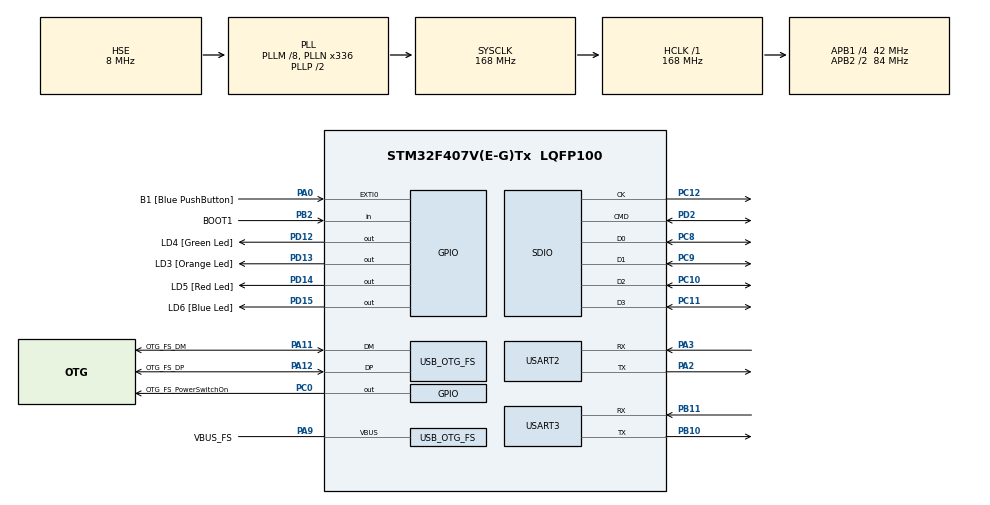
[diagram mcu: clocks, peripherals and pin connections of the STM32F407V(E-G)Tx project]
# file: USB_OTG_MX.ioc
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Mcu.Family=STM32F4
Mcu.Name=STM32F407V(E-G)Tx
Mcu.Package=LQFP100
NVIC.OTG_FS_IRQn=true\:0\:0\:false\:false\:true\:true
NVIC.PriorityGroup=NVIC_PRIORITYGROUP_0
NVIC.USART2_IRQn=true\:0\:0\:false\:false\:true\:true
NVIC.USART3_IRQn=true\:0\:0\:false\:false\:true\:true
PA0-WKUP.GPIO_Label=B1 [Blue PushButton]
PA0-WKUP.GPIO_ModeDefaultEXTI=GPIO_MODE_EVT_RISING
PA0-WKUP.GPIO_PuPd=GPIO_NOPULL
PA0-WKUP.Signal=GPXTI0
PA10.Signal=USB_OTG_FS_ID
PA11.GPIO_Label=OTG_FS_DM
PA11.GPIO_Mode=GPIO_MODE_AF_PP
PA11.GPIO_PuPd=GPIO_NOPULL
PA11.GPIO_Speed=GPIO_SPEED_FREQ_LOW
PA11.Mode=Device_Only
PA11.Signal=USB_OTG_FS_DM
PA12.GPIO_Label=OTG_FS_DP
PA12.GPIO_Mode=GPIO_MODE_AF_PP
PA12.GPIO_PuPd=GPIO_NOPULL
PA12.GPIO_Speed=GPIO_SPEED_FREQ_LOW
PA12.Mode=Device_Only
PA12.Signal=USB_OTG_FS_DP
PA13.GPIO_Label=SWDIO
PA13.Signal=SYS_JTMS-SWDIO
PA14.GPIO_Label=SWCLK
PA14.Signal=SYS_JTCK-SWCLK
PA2.Mode=Asynchronous
PA2.Signal=USART2_TX
PA3.Mode=Asynchronous
PA3.Signal=USART2_RX
PA9.GPIO_Label=VBUS_FS
PA9.GPIO_Mode=GPIO_MODE_INPUT
PA9.GPIO_PuPd=GPIO_NOPULL
PA9.Mode=Activate_VBUS
PA9.Signal=USB_OTG_FS_VBUS
PB10.Mode=Asynchronous
PB10.Signal=USART3_TX
PB11.Mode=Asynchronous
PB11.Signal=USART3_RX
PB2.GPIO_Label=BOOT1
PB2.GPIO_Mode=GPIO_MODE_INPUT
PB2.GPIO_PuPd=GPIO_NOPULL
PB2.Signal=GPIO_Input
PB3.GPIO_Label=SWO
PB3.Signal=SYS_JTDO-SWO
PC0.GPIO_Label=OTG_FS_PowerSwitchOn
PC0.GPIO_PuPd=GPIO_NOPULL
PC0.GPIO_Speed=GPIO_SPEED_FREQ_LOW
PC0.PinState=GPIO_PIN_SET
PC0.Signal=GPIO_Output
PC10.Mode=SD_4_bits_Wide_bus
PC10.Signal=SDIO_D2
PC11.Mode=SD_4_bits_Wide_bus
PC11.Signal=SDIO_D3
PC12.Mode=SD_4_bits_Wide_bus
PC12.Signal=SDIO_CK
PC14-OSC32_IN.GPIO_Label=PC14-OSC32_IN
PC14-OSC32_IN.Signal=RCC_OSC32_IN
PC15-OSC32_OUT.GPIO_Label=PC15-OSC32_OUT
PC15-OSC32_OUT.Signal=RCC_OSC32_OUT
PC8.Mode=SD_4_bits_Wide_bus
PC8.Signal=SDIO_D0
PC9.Mode=SD_4_bits_Wide_bus
PC9.Signal=SDIO_D1
PD12.GPIO_Label=LD4 [Green Led]
PD12.GPIO_PuPd=GPIO_NOPULL
PD12.GPIO_Speed=GPIO_SPEED_FREQ_LOW
PD12.Signal=GPIO_Output
PD13.GPIO_Label=LD3 [Orange Led]
PD13.GPIO_PuPd=GPIO_NOPULL
PD13.GPIO_Speed=GPIO_SPEED_FREQ_LOW
PD13.Signal=GPIO_Output
PD14.GPIO_Label=LD5 [Red Led]
PD14.GPIO_PuPd=GPIO_NOPULL
PD14.GPIO_Speed=GPIO_SPEED_FREQ_LOW
PD14.Signal=GPIO_Output
PD15.GPIO_Label=LD6 [Blue Led]
PD15.GPIO_PuPd=GPIO_NOPULL
PD15.GPIO_Speed=GPIO_SPEED_FREQ_LOW
PD15.Signal=GPIO_Output
PD2.Mode=SD_4_bits_Wide_bus
PD2.Signal=SDIO_CMD
PH0-OSC_IN.GPIO_Label=PH0-OSC_IN
PH0-OSC_IN.Mode=HSE-External-Oscillator
PH0-OSC_IN.Signal=RCC_OSC_IN
PH1-OSC_OUT.GPIO_Label=PH1-OSC_OUT
PH1-OSC_OUT.Mode=HSE-External-Oscillator
PH1-OSC_OUT.Signal=RCC_OSC_OUT
ProjectManager.HeapSize=0x200
ProjectManager.StackSize=0x400
ProjectManager.TargetToolchain=TrueSTUDIO
RCC.48MHZClocksFreq_Value=48000000
RCC.AHBFreq_Value=168000000
RCC.APB1CLKDivider=RCC_HCLK_DIV4
RCC.APB1Freq_Value=42000000
RCC.APB1TimFreq_Value=84000000
RCC.APB2CLKDivider=RCC_HCLK_DIV2
RCC.APB2Freq_Value=84000000
RCC.APB2TimFreq_Value=168000000
RCC.CortexFreq_Value=168000000
RCC.HCLKFreq_Value=168000000
RCC.HSE_VALUE=8000000
RCC.HSI_VALUE=16000000
RCC.LSE_VALUE=32768
RCC.PLLM=8
RCC.PLLN=336
RCC.PLLQ=7
RCC.SYSCLKFreq_VALUE=168000000
RCC.SYSCLKSource=RCC_SYSCLKSOURCE_PLLCLK
RCC.VCOOutputFreq_Value=336000000
USART2.VirtualMode=VM_ASYNC
USART3.VirtualMode=VM_ASYNC
USB_DEVICE.USBD_HandleTypeDef-MSC_FS=hUsbDeviceFS
USB_DEVICE.USBD_SUPPORT_USER_STRING-MSC_FS=1
USB_DEVICE.VirtualMode-MSC_FS=Msc
USB_DEVICE.VirtualModeFS=Msc_FS
USB_OTG_FS.VirtualMode=Device_Only
USB_OTG_FS.low_power_enable=DISABLE
USB_OTG_FS.lpm_enable=DISABLE
USB_OTG_FS.vbus_sensing_enable=ENABLE
VP_FATFS_VS_SDIO.Mode=SDIO
VP_USB_DEVICE_VS_USB_DEVICE_MSC_FS.Mode=MSC_FS
board=STM32F4DISCOVERY

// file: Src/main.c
/**
  ******************************************************************************
  * File Name          : main.c
  * Description        : Main program body
  ******************************************************************************
  *
  * COPYRIGHT(c) 2016 STMicroelectronics
  *
  * Redistribution and use in source and binary forms, with or without modification,
  * are permitted provided that the following conditions are met:
  *   1. Redistributions of source code must retain the above copyright notice,
  *      this list of conditions and the following disclaimer.
  *   2. Redistributions in binary form must reproduce the above copyright notice,
  *      this list of conditions and the following disclaimer in the documentation
  *      and/or other materials provided with the distribution.
  *   3. Neither the name of STMicroelectronics nor the names of its contributors
  *      may be used to endorse or promote products derived from this software
  *      without specific prior written permission.
  *
  * THIS SOFTWARE IS PROVIDED BY THE COPYRIGHT HOLDERS AND CONTRIBUTORS "AS IS"
  * AND ANY EXPRESS OR IMPLIED WARRANTIES, INCLUDING, BUT NOT LIMITED TO, THE
  * IMPLIED WARRANTIES OF MERCHANTABILITY AND FITNESS FOR A PARTICULAR PURPOSE ARE
  * DISCLAIMED. IN NO EVENT SHALL THE COPYRIGHT HOLDER OR CONTRIBUTORS BE LIABLE
  * FOR ANY DIRECT, INDIRECT, INCIDENTAL, SPECIAL, EXEMPLARY, OR CONSEQUENTIAL
  * DAMAGES (INCLUDING, BUT NOT LIMITED TO, PROCUREMENT OF SUBSTITUTE GOODS OR
  * SERVICES; LOSS OF USE, DATA, OR PROFITS; OR BUSINESS INTERRUPTION) HOWEVER
  * CAUSED AND ON ANY THEORY OF LIABILITY, WHETHER IN CONTRACT, STRICT LIABILITY,
  * OR TORT (INCLUDING NEGLIGENCE OR OTHERWISE) ARISING IN ANY WAY OUT OF THE USE
  * OF THIS SOFTWARE, EVEN IF ADVISED OF THE POSSIBILITY OF SUCH DAMAGE.
  *
  ******************************************************************************
  */
#include "stm32f4xx_hal.h"
#include "fatfs.h"
#include "usb_device.h"

/* USER CODE BEGIN Includes */
#include "functions.h"
/* USER CODE END Includes */

SD_HandleTypeDef hsd;
HAL_SD_CardInfoTypedef SDCardInfo;

UART_HandleTypeDef huart2;
UART_HandleTypeDef huart3;

/* USER CODE BEGIN PV */
/* Private variables ---------------------------------------------------------*/

/* USER CODE END PV */

void SystemClock_Config(void);
void Error_Handler(void);
static void MX_GPIO_Init(void);
static void MX_SDIO_SD_Init(void);
static void MX_USART2_UART_Init(void);
static void MX_USART3_UART_Init(void);

/* USER CODE BEGIN PFP */
/* Private function prototypes -----------------------------------------------*/
#define HAL_UART_MODULE_ENABLED
/* USER CODE END PFP */

extern volatile uint8_t TxFlag;
int main(void)
{

  /* MCU Configuration----------------------------------------------------------*/

  /* Reset of all peripherals, Initializes the Flash interface and the Systick. */
  HAL_Init();

  /* Configure the system clock */
  SystemClock_Config();

  /* Initialize all configured peripherals */
  MX_GPIO_Init();
  MX_SDIO_SD_Init();
  MX_USB_DEVICE_Init();
  MX_FATFS_Init();
  MX_USART2_UART_Init();
  MX_USART3_UART_Init();
  Disk_Init();
  InitStateMashine();

  /* Infinite loop */
  /* USER CODE BEGIN WHILE */
  //HAL_UART_Receive_IT(&huart3,&UART_Data,1);
  while (1)
  {
	//UART_RX();
	stateMashin();
	control_in_buf();
  /* USER CODE END WHILE */

  }

}

/** System Clock Configuration
*/
void SystemClock_Config(void)
{

  RCC_OscInitTypeDef RCC_OscInitStruct;
  RCC_ClkInitTypeDef RCC_ClkInitStruct;

  __HAL_RCC_PWR_CLK_ENABLE();

  __HAL_PWR_VOLTAGESCALING_CONFIG(PWR_REGULATOR_VOLTAGE_SCALE1);

  RCC_OscInitStruct.OscillatorType = RCC_OSCILLATORTYPE_HSE;
  RCC_OscInitStruct.HSEState = RCC_HSE_ON;
  RCC_OscInitStruct.PLL.PLLState = RCC_PLL_ON;
  RCC_OscInitStruct.PLL.PLLSource = RCC_PLLSOURCE_HSE;
  RCC_OscInitStruct.PLL.PLLM = 8;
  RCC_OscInitStruct.PLL.PLLN = 336;
  RCC_OscInitStruct.PLL.PLLP = RCC_PLLP_DIV2;
  RCC_OscInitStruct.PLL.PLLQ = 7;
  if (HAL_RCC_OscConfig(&RCC_OscInitStruct) != HAL_OK)
  {
    Error_Handler();
  }

  RCC_ClkInitStruct.ClockType = RCC_CLOCKTYPE_HCLK|RCC_CLOCKTYPE_SYSCLK
                              |RCC_CLOCKTYPE_PCLK1|RCC_CLOCKTYPE_PCLK2;
  RCC_ClkInitStruct.SYSCLKSource = RCC_SYSCLKSOURCE_PLLCLK;
  RCC_ClkInitStruct.AHBCLKDivider = RCC_SYSCLK_DIV1;
  RCC_ClkInitStruct.APB1CLKDivider = RCC_HCLK_DIV4;
  RCC_ClkInitStruct.APB2CLKDivider = RCC_HCLK_DIV2;
  if (HAL_RCC_ClockConfig(&RCC_ClkInitStruct, FLASH_LATENCY_5) != HAL_OK)
  {
    Error_Handler();
  }

  HAL_SYSTICK_Config(HAL_RCC_GetHCLKFreq()/1000);

  HAL_SYSTICK_CLKSourceConfig(SYSTICK_CLKSOURCE_HCLK);

  /* SysTick_IRQn interrupt configuration */
  HAL_NVIC_SetPriority(SysTick_IRQn, 0, 0);
}

/* SDIO init function */
static void MX_SDIO_SD_Init(void)
{

  hsd.Instance = SDIO;
  hsd.Init.ClockEdge = SDIO_CLOCK_EDGE_RISING;
  hsd.Init.ClockBypass = SDIO_CLOCK_BYPASS_DISABLE;
  hsd.Init.ClockPowerSave = SDIO_CLOCK_POWER_SAVE_DISABLE;
  hsd.Init.BusWide = SDIO_BUS_WIDE_1B;
  hsd.Init.HardwareFlowControl = SDIO_HARDWARE_FLOW_CONTROL_DISABLE;
  hsd.Init.ClockDiv = 4;
/*  if(HAL_SD_Init(&hsd,&SDCardInfo)!=SD_OK)
	  {
		  Error_Handler();
	  }*/

}

/* USART2 init function */
static void MX_USART2_UART_Init(void)
{

  huart2.Instance = USART2;
  huart2.Init.BaudRate = 115200;
  huart2.Init.WordLength = UART_WORDLENGTH_8B;
  huart2.Init.StopBits = UART_STOPBITS_1;
  huart2.Init.Parity = UART_PARITY_NONE;
  huart2.Init.Mode = UART_MODE_TX_RX;
  huart2.Init.HwFlowCtl = UART_HWCONTROL_NONE;
  huart2.Init.OverSampling = UART_OVERSAMPLING_16;
  if (HAL_UART_Init(&huart2) != HAL_OK)
  {
    Error_Handler();
  }

}

/* USART3 init function */
static void MX_USART3_UART_Init(void)
{

  huart3.Instance = USART3;
  huart3.Init.BaudRate = 115200;
  huart3.Init.WordLength = UART_WORDLENGTH_8B;
  huart3.Init.StopBits = UART_STOPBITS_1;
  huart3.Init.Parity = UART_PARITY_NONE;
  huart3.Init.Mode = UART_MODE_TX_RX;
  huart3.Init.HwFlowCtl = UART_HWCONTROL_NONE;
  huart3.Init.OverSampling = UART_OVERSAMPLING_16;
  if (HAL_UART_Init(&huart3) != HAL_OK)
  {
    Error_Handler();
  }

}

/** Configure pins as
        * Analog
        * Input
        * Output
        * EVENT_OUT
        * EXTI
*/
static void MX_GPIO_Init(void)
{

  GPIO_InitTypeDef GPIO_InitStruct;

  /* GPIO Ports Clock Enable */
  __HAL_RCC_GPIOC_CLK_ENABLE();
  __HAL_RCC_GPIOH_CLK_ENABLE();
  __HAL_RCC_GPIOA_CLK_ENABLE();
  __HAL_RCC_GPIOB_CLK_ENABLE();
  __HAL_RCC_GPIOD_CLK_ENABLE();

  /*Configure GPIO pin Output Level */
  HAL_GPIO_WritePin(OTG_FS_PowerSwitchOn_GPIO_Port, OTG_FS_PowerSwitchOn_Pin, GPIO_PIN_SET);

  /*Configure GPIO pin Output Level */
  HAL_GPIO_WritePin(GPIOD, LD4_Pin|LD3_Pin|LD5_Pin|LD6_Pin, GPIO_PIN_RESET);

  /*Configure GPIO pin : OTG_FS_PowerSwitchOn_Pin */
  GPIO_InitStruct.Pin = OTG_FS_PowerSwitchOn_Pin;
  GPIO_InitStruct.Mode = GPIO_MODE_OUTPUT_PP;
  GPIO_InitStruct.Pull = GPIO_NOPULL;
  GPIO_InitStruct.Speed = GPIO_SPEED_FREQ_LOW;
  HAL_GPIO_Init(OTG_FS_PowerSwitchOn_GPIO_Port, &GPIO_InitStruct);

  /*Configure GPIO pin : B1_Pin */
  GPIO_InitStruct.Pin = B1_Pin;
  GPIO_InitStruct.Mode = GPIO_MODE_EVT_RISING;
  GPIO_InitStruct.Pull = GPIO_NOPULL;
  HAL_GPIO_Init(B1_GPIO_Port, &GPIO_InitStruct);

  /*Configure GPIO pin : BOOT1_Pin */
  GPIO_InitStruct.Pin = BOOT1_Pin;
  GPIO_InitStruct.Mode = GPIO_MODE_INPUT;
  GPIO_InitStruct.Pull = GPIO_NOPULL;
  HAL_GPIO_Init(BOOT1_GPIO_Port, &GPIO_InitStruct);

  /*Configure GPIO pins : LD4_Pin LD3_Pin LD5_Pin LD6_Pin */
  GPIO_InitStruct.Pin = LD4_Pin|LD3_Pin|LD5_Pin|LD6_Pin;
  GPIO_InitStruct.Mode = GPIO_MODE_OUTPUT_PP;
  GPIO_InitStruct.Pull = GPIO_NOPULL;
  GPIO_InitStruct.Speed = GPIO_SPEED_FREQ_LOW;
  HAL_GPIO_Init(GPIOD, &GPIO_InitStruct);

}

void Error_Handler(void)
{
  /* USER CODE BEGIN Error_Handler */
  /* User can add his own implementation to report the HAL error return state */
  while(1)
  {
	  HAL_GPIO_TogglePin(GPIOD, LD4_Pin);
	  HAL_Delay(500);
  }
  /* USER CODE END Error_Handler */
}

/************************ (C) COPYRIGHT STMicroelectronics *****END OF FILE****/
